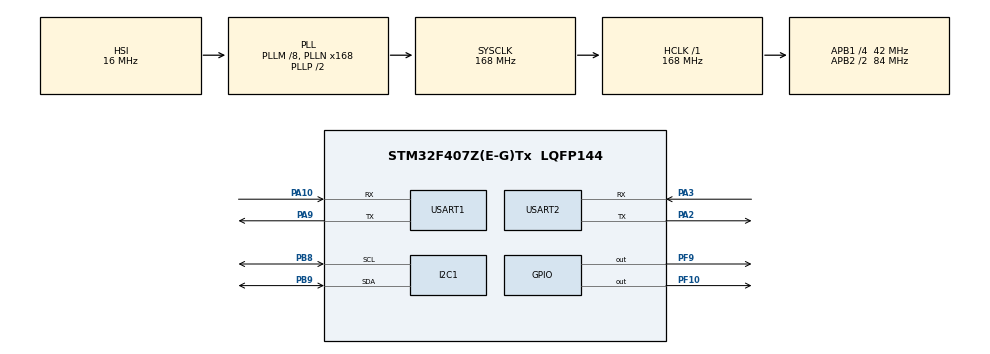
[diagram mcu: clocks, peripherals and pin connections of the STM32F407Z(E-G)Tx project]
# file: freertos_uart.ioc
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Dma.Request0=USART1_RX
Dma.Request1=USART1_TX
Dma.Request2=USART2_RX
Dma.Request3=USART2_TX
Dma.USART1_RX.0.Direction=DMA_PERIPH_TO_MEMORY
Dma.USART1_RX.0.FIFOMode=DMA_FIFOMODE_DISABLE
Dma.USART1_RX.0.Instance=DMA2_Stream2
Dma.USART1_RX.0.MemDataAlignment=DMA_MDATAALIGN_BYTE
Dma.USART1_RX.0.MemInc=DMA_MINC_ENABLE
Dma.USART1_RX.0.Mode=DMA_CIRCULAR
Dma.USART1_RX.0.PeriphDataAlignment=DMA_PDATAALIGN_BYTE
Dma.USART1_RX.0.PeriphInc=DMA_PINC_DISABLE
Dma.USART1_RX.0.Priority=DMA_PRIORITY_LOW
Dma.USART1_TX.1.Direction=DMA_MEMORY_TO_PERIPH
Dma.USART1_TX.1.FIFOMode=DMA_FIFOMODE_DISABLE
Dma.USART1_TX.1.Instance=DMA2_Stream7
Dma.USART1_TX.1.MemDataAlignment=DMA_MDATAALIGN_BYTE
Dma.USART1_TX.1.MemInc=DMA_MINC_ENABLE
Dma.USART1_TX.1.Mode=DMA_NORMAL
Dma.USART1_TX.1.PeriphDataAlignment=DMA_PDATAALIGN_BYTE
Dma.USART1_TX.1.PeriphInc=DMA_PINC_DISABLE
Dma.USART1_TX.1.Priority=DMA_PRIORITY_LOW
Dma.USART2_RX.2.Direction=DMA_PERIPH_TO_MEMORY
Dma.USART2_RX.2.FIFOMode=DMA_FIFOMODE_DISABLE
Dma.USART2_RX.2.Instance=DMA1_Stream5
Dma.USART2_RX.2.MemDataAlignment=DMA_MDATAALIGN_BYTE
Dma.USART2_RX.2.MemInc=DMA_MINC_ENABLE
Dma.USART2_RX.2.Mode=DMA_CIRCULAR
Dma.USART2_RX.2.PeriphDataAlignment=DMA_PDATAALIGN_BYTE
Dma.USART2_RX.2.PeriphInc=DMA_PINC_DISABLE
Dma.USART2_RX.2.Priority=DMA_PRIORITY_LOW
Dma.USART2_TX.3.Direction=DMA_MEMORY_TO_PERIPH
Dma.USART2_TX.3.FIFOMode=DMA_FIFOMODE_DISABLE
Dma.USART2_TX.3.Instance=DMA1_Stream6
Dma.USART2_TX.3.MemDataAlignment=DMA_MDATAALIGN_BYTE
Dma.USART2_TX.3.MemInc=DMA_MINC_ENABLE
Dma.USART2_TX.3.Mode=DMA_NORMAL
Dma.USART2_TX.3.PeriphDataAlignment=DMA_PDATAALIGN_BYTE
Dma.USART2_TX.3.PeriphInc=DMA_PINC_DISABLE
Dma.USART2_TX.3.Priority=DMA_PRIORITY_LOW
FREERTOS.Tasks01=defaultTask,24,128,StartDefaultTask,Default,NULL,Dynamic,NULL,NULL
Mcu.Family=STM32F4
Mcu.Name=STM32F407Z(E-G)Tx
Mcu.Package=LQFP144
NVIC.DMA1_Stream5_IRQn=true\:5\:0\:false\:false\:true\:true\:false\:true\:true
NVIC.DMA1_Stream6_IRQn=true\:5\:0\:false\:false\:true\:true\:false\:true\:true
NVIC.DMA2_Stream2_IRQn=true\:5\:0\:false\:false\:true\:true\:false\:true\:true
NVIC.DMA2_Stream7_IRQn=true\:5\:0\:true\:false\:true\:true\:false\:true\:true
NVIC.PriorityGroup=NVIC_PRIORITYGROUP_4
NVIC.TIM1_UP_TIM10_IRQn=true\:15\:0\:false\:false\:true\:false\:false\:true\:true
NVIC.TimeBase=TIM1_UP_TIM10_IRQn
NVIC.TimeBaseIP=TIM1
NVIC.USART1_IRQn=true\:5\:0\:false\:false\:true\:true\:false\:true\:true
NVIC.USART2_IRQn=true\:5\:0\:false\:false\:true\:true\:true\:true\:true
PA10.Mode=Asynchronous
PA10.Signal=USART1_RX
PA13.Mode=Serial_Wire
PA13.Signal=SYS_JTMS-SWDIO
PA14.Mode=Serial_Wire
PA14.Signal=SYS_JTCK-SWCLK
PA2.Mode=Asynchronous
PA2.Signal=USART2_TX
PA3.Mode=Asynchronous
PA3.Signal=USART2_RX
PA9.Mode=Asynchronous
PA9.Signal=USART1_TX
PB8.Mode=I2C
PB8.Signal=I2C1_SCL
PB9.Mode=I2C
PB9.Signal=I2C1_SDA
PF10.PinState=GPIO_PIN_SET
PF10.Signal=GPIO_Output
PF9.Signal=GPIO_Output
ProjectManager.HeapSize=0x200
ProjectManager.StackSize=0x400
ProjectManager.TargetToolchain=MDK-ARM V5.32
RCC.48MHZClocksFreq_Value=84000000
RCC.AHBFreq_Value=168000000
RCC.APB1CLKDivider=RCC_HCLK_DIV4
RCC.APB1Freq_Value=42000000
RCC.APB1TimFreq_Value=84000000
RCC.APB2CLKDivider=RCC_HCLK_DIV2
RCC.APB2Freq_Value=84000000
RCC.APB2TimFreq_Value=168000000
RCC.CortexFreq_Value=168000000
RCC.HCLKFreq_Value=168000000
RCC.HSE_VALUE=25000000
RCC.HSI_VALUE=16000000
RCC.LSE_VALUE=32768
RCC.PLLM=8
RCC.PLLN=168
RCC.SYSCLKFreq_VALUE=168000000
RCC.SYSCLKSource=RCC_SYSCLKSOURCE_PLLCLK
RCC.VCOOutputFreq_Value=336000000
USART1.VirtualMode=VM_ASYNC
USART2.VirtualMode=VM_ASYNC
VP_FREERTOS_VS_CMSIS_V2.Mode=CMSIS_V2
VP_SYS_VS_tim1.Mode=TIM1
board=custom

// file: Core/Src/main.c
/* USER CODE BEGIN Header */
/**
  ******************************************************************************
  * @file           : main.c
  * @brief          : Main program body
  ******************************************************************************
  * @attention
  *
  * Copyright (c) 2026 STMicroelectronics.
  * All rights reserved.
  *
  * This software is licensed under terms that can be found in the LICENSE file
  * in the root directory of this software component.
  * If no LICENSE file comes with this software, it is provided AS-IS.
  *
  ******************************************************************************
  */
/* USER CODE END Header */
#include "main.h"
#include "cmsis_os.h"
#include "dma.h"
#include "i2c.h"
#include "usart.h"
#include "gpio.h"

/* USER CODE BEGIN Includes */
#include "circle_buffer.h"
/* USER CODE END Includes */

/* USER CODE BEGIN PV */
extern UART_HandleTypeDef huart1;

/* USER CODE END PV */

void SystemClock_Config(void);
void MX_FREERTOS_Init(void);

int main(void)
{

  /* USER CODE BEGIN 1 */
//	char c;
//	int len;
//	char *str = "www.100ask.net\r\n";
  /* USER CODE END 1 */

  /* MCU Configuration--------------------------------------------------------*/

  /* Reset of all peripherals, Initializes the Flash interface and the Systick. */
  HAL_Init();

  /* Configure the system clock */
  SystemClock_Config();

  /* Initialize all configured peripherals */
  MX_GPIO_Init();
  MX_DMA_Init();
  MX_USART1_UART_Init();
  MX_I2C1_Init();
  MX_USART2_UART_Init();
  /* USER CODE BEGIN 2 */

//	HAL_UART_Transmit(&huart1, str, strlen(str), 1000);
	/* use HAL_UART_Receive_IT来使能RXNE中断 */

  /* USER CODE END 2 */

  /* Init scheduler */
  osKernelInitialize();  /* Call init function for freertos objects (in cmsis_os2.c) */
  MX_FREERTOS_Init();

  /* Start scheduler */
  osKernelStart();

  /* We should never get here as control is now taken by the scheduler */

  /* Infinite loop */
  while (1)
  {

  }
}

void SystemClock_Config(void)
{
  RCC_OscInitTypeDef RCC_OscInitStruct = {0};
  RCC_ClkInitTypeDef RCC_ClkInitStruct = {0};

  /** Configure the main internal regulator output voltage
  */
  __HAL_RCC_PWR_CLK_ENABLE();
  __HAL_PWR_VOLTAGESCALING_CONFIG(PWR_REGULATOR_VOLTAGE_SCALE1);

  /** Initializes the RCC Oscillators according to the specified parameters
  * in the RCC_OscInitTypeDef structure.
  */
  RCC_OscInitStruct.OscillatorType = RCC_OSCILLATORTYPE_HSI;
  RCC_OscInitStruct.HSIState = RCC_HSI_ON;
  RCC_OscInitStruct.HSICalibrationValue = RCC_HSICALIBRATION_DEFAULT;
  RCC_OscInitStruct.PLL.PLLState = RCC_PLL_ON;
  RCC_OscInitStruct.PLL.PLLSource = RCC_PLLSOURCE_HSI;
  RCC_OscInitStruct.PLL.PLLM = 8;
  RCC_OscInitStruct.PLL.PLLN = 168;
  RCC_OscInitStruct.PLL.PLLP = RCC_PLLP_DIV2;
  RCC_OscInitStruct.PLL.PLLQ = 4;
  if (HAL_RCC_OscConfig(&RCC_OscInitStruct) != HAL_OK)
  {
    Error_Handler();
  }

  /** Initializes the CPU, AHB and APB buses clocks
  */
  RCC_ClkInitStruct.ClockType = RCC_CLOCKTYPE_HCLK|RCC_CLOCKTYPE_SYSCLK
                              |RCC_CLOCKTYPE_PCLK1|RCC_CLOCKTYPE_PCLK2;
  RCC_ClkInitStruct.SYSCLKSource = RCC_SYSCLKSOURCE_PLLCLK;
  RCC_ClkInitStruct.AHBCLKDivider = RCC_SYSCLK_DIV1;
  RCC_ClkInitStruct.APB1CLKDivider = RCC_HCLK_DIV4;
  RCC_ClkInitStruct.APB2CLKDivider = RCC_HCLK_DIV2;

  if (HAL_RCC_ClockConfig(&RCC_ClkInitStruct, FLASH_LATENCY_5) != HAL_OK)
  {
    Error_Handler();
  }
}

void HAL_TIM_PeriodElapsedCallback(TIM_HandleTypeDef *htim)
{
  if (htim->Instance == TIM1)
  {
    HAL_IncTick();
  }
}

void Error_Handler(void)
{
  __disable_irq();
  while (1)
  {
  }
}

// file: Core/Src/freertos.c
/* USER CODE BEGIN Header */
/**
  ******************************************************************************
  * File Name          : freertos.c
  * Description        : Code for freertos applications
  ******************************************************************************
  * @attention
  *
  * Copyright (c) 2026 STMicroelectronics.
  * All rights reserved.
  *
  * This software is licensed under terms that can be found in the LICENSE file
  * in the root directory of this software component.
  * If no LICENSE file comes with this software, it is provided AS-IS.
  *
  ******************************************************************************
  */
/* USER CODE END Header */

#include "FreeRTOS.h"
#include "task.h"
#include "main.h"
#include "cmsis_os.h"

/* USER CODE BEGIN Includes */
#include "uart_device.h"
#include "mqttclient_test.h"
/* USER CODE END Includes */

/* Definitions for defaultTask */
osThreadId_t defaultTaskHandle;
const osThreadAttr_t defaultTask_attributes = {
  .name = "defaultTask",
  .stack_size = 128 * 4,
  .priority = (osPriority_t) osPriorityNormal,
};

/* USER CODE BEGIN FunctionPrototypes */
extern void tcp_client_test_task(void *arg);

#define TCP_CLIENT_TASK_STACK_SIZE   512        /* 单位是字（word），不是字节 */
#define TCP_CLIENT_TASK_PRIORITY     (osPriorityNormal)

//static TaskHandle_t s_tcp_client_handle = NULL;

/* USER CODE END FunctionPrototypes */

void StartDefaultTask(void *argument);

void MX_FREERTOS_Init(void); /* (MISRA C 2004 rule 8.1) */

void MX_FREERTOS_Init(void) {

  /* USER CODE BEGIN RTOS_QUEUES */
  /* add queues, ... */
//	xTaskCreate(
//        tcp_client_test_task,          /* 任务函数 */
//        "tcp_client",                  /* 任务名，调试用 */
//        TCP_CLIENT_TASK_STACK_SIZE,    /* 栈深度，单位：字 */
//        NULL,                          /* 传给任务的参数 arg */
//        TCP_CLIENT_TASK_PRIORITY,      /* 优先级 */
//        &s_tcp_client_handle);         /* 任务句柄，不需要可传 NULL */
  /* USER CODE END RTOS_QUEUES */

  /* Create the thread(s) */
  /* creation of defaultTask */
  defaultTaskHandle = osThreadNew(StartDefaultTask, NULL, &defaultTask_attributes);

}

void StartDefaultTask(void *argument)
{
  /* USER CODE BEGIN StartDefaultTask */

//  PUART_Device uart = Get_UART_Device("stm32_f4_uart2");
//  if (uart == NULL)
//  {
//    while(1)
//    {
//       osDelay(1);
//    }
//  }
//  uart->UART_Init(uart, 115200, 8, 'N', 1);
//  process_cmd_task();
//extern void flash_test_run(void);
//flash_test_run();
		extern void start_webserver(void);
    start_webserver();
		//esp8266_wifi_connect("Tenda", "wxw123456");
	//MQTTClientTask(NULL);
  //   extern int esp8266_wifi_connect(char *ssid, char *password);
  // esp8266_wifi_connect("Tenda", "wxw123456");
  /* Infinite loop */
  for(;;)
  {
//		HAL_GPIO_WritePin(GPIOF, GPIO_PIN_9, GPIO_PIN_RESET);
//    vTaskDelay(500);
//    HAL_GPIO_WritePin(GPIOF, GPIO_PIN_9, GPIO_PIN_SET);
    vTaskDelay(500);
//    if(0 == uart1->UART_Recv(uart1, &data, 1))
//    {
//       uart1->UART_Send(uart1, &data, 1, 1);
//    }
//		    if(0 == uart->UART_Recv(uart, &data, 1))
//    {
//       uart->UART_Send(uart, &data, 1, 1);
//    }
    osDelay(1);
  }
  /* USER CODE END StartDefaultTask */
}
